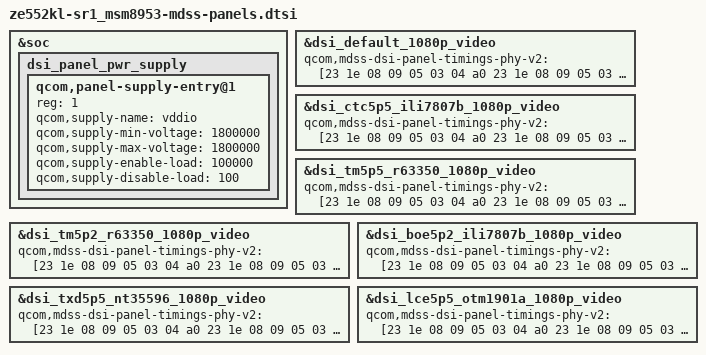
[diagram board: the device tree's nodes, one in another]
/* Copyright (c) 2015-2017, The Linux Foundation. All rights reserved.
 *
 * This program is free software; you can redistribute it and/or modify
 * it under the terms of the GNU General Public License version 2 and
 * only version 2 as published by the Free Software Foundation.
 *
 * This program is distributed in the hope that it will be useful,
 * but WITHOUT ANY WARRANTY; without even the implied warranty of
 * MERCHANTABILITY or FITNESS FOR A PARTICULAR PURPOSE.  See the
 * GNU General Public License for more details.
 */

/*#include "dsi-panel-sim-video.dtsi"
#include "dsi-panel-sim-dualmipi-video.dtsi"
#include "dsi-panel-sim-cmd.dtsi"
#include "dsi-panel-sim-dualmipi-cmd.dtsi"
#include "dsi-panel-truly-1080p-video.dtsi"
#include "dsi-panel-truly-1080p-cmd.dtsi"
#include "dsi-adv7533-1080p.dtsi"
#include "dsi-adv7533-720p.dtsi"
#include "dsi-panel-r69006-1080p-video.dtsi"
#include "dsi-panel-r69006-1080p-cmd.dtsi"
#include "dsi-panel-truly-wuxga-video.dtsi"
#include "dsi-panel-lt8912-480p-video.dtsi"
#include "dsi-panel-lt8912-1080p-video.dtsi"*/
#include "dsi-panel-default-1080p-video.dtsi"
#include "dsi-panel-ctc5p5-ili7807b-1080p-video.dtsi"
#include "dsi-panel-tm5p5-r63350-1080p-video.dtsi"
#include "dsi-panel-tm5p2-r63350-1080p-video.dtsi"
#include "dsi-panel-boe5p2-ili7807b-1080p-video.dtsi"
#include "dsi-panel-txd5p5-nt35596-1080p-video.dtsi"
#include "dsi-panel-lce5p5-otm1901a-1080p-video.dtsi"

&soc {
	dsi_panel_pwr_supply: dsi_panel_pwr_supply {
		#address-cells = <1>;
		#size-cells = <0>;

		/*qcom,panel-supply-entry@0 {
			reg = <0>;
			qcom,supply-name = "vdd";
			qcom,supply-min-voltage = <2850000>;
			qcom,supply-max-voltage = <2850000>;
			qcom,supply-enable-load = <100000>;
			qcom,supply-disable-load = <100>;
		};*/

		qcom,panel-supply-entry@1 {
			reg = <1>;
			qcom,supply-name = "vddio";
			qcom,supply-min-voltage = <1800000>;
			qcom,supply-max-voltage = <1800000>;
			qcom,supply-enable-load = <100000>;
			qcom,supply-disable-load = <100>;
		};
	};
};

&dsi_default_1080p_video {
	qcom,mdss-dsi-panel-timings-phy-v2 = [23 1e 08 09 05 03 04 a0
		23 1e 08 09 05 03 04 a0
		23 1e 08 09 05 03 04 a0
		23 1e 08 09 05 03 04 a0
		23 1a 08 09 05 03 04 a0];
};

&dsi_ctc5p5_ili7807b_1080p_video {
	qcom,mdss-dsi-panel-timings-phy-v2 = [23 1e 08 09 05 03 04 a0
		23 1e 08 09 05 03 04 a0
		23 1e 08 09 05 03 04 a0
		23 1e 08 09 05 03 04 a0
		23 1a 08 09 05 03 04 a0];
};

&dsi_tm5p5_r63350_1080p_video {
	qcom,mdss-dsi-panel-timings-phy-v2 = [23 1e 08 09 05 03 04 a0
		23 1e 08 09 05 03 04 a0
		23 1e 08 09 05 03 04 a0
		23 1e 08 09 05 03 04 a0
		23 1a 08 09 05 03 04 a0];
};

&dsi_tm5p2_r63350_1080p_video {
	qcom,mdss-dsi-panel-timings-phy-v2 = [23 1e 08 09 05 03 04 a0
		23 1e 08 09 05 03 04 a0
		23 1e 08 09 05 03 04 a0
		23 1e 08 09 05 03 04 a0
		23 1a 08 09 05 03 04 a0];
};

&dsi_boe5p2_ili7807b_1080p_video {
	qcom,mdss-dsi-panel-timings-phy-v2 = [23 1e 08 09 05 03 04 a0
		23 1e 08 09 05 03 04 a0
		23 1e 08 09 05 03 04 a0
		23 1e 08 09 05 03 04 a0
		23 1a 08 09 05 03 04 a0];
};

&dsi_txd5p5_nt35596_1080p_video {
	qcom,mdss-dsi-panel-timings-phy-v2 = [23 1e 08 09 05 03 04 a0
		23 1e 08 09 05 03 04 a0
		23 1e 08 09 05 03 04 a0
		23 1e 08 09 05 03 04 a0
		23 1a 08 09 05 03 04 a0];
};

&dsi_lce5p5_otm1901a_1080p_video {
	qcom,mdss-dsi-panel-timings-phy-v2 = [23 1e 08 09 05 03 04 a0
		23 1e 08 09 05 03 04 a0
		23 1e 08 09 05 03 04 a0
		23 1e 08 09 05 03 04 a0
		23 1a 08 09 05 03 04 a0];
};

/*&dsi_truly_1080_vid {
	qcom,mdss-dsi-panel-timings-phy-v2 = [23 1e 08 09 05 03 04 a0
		23 1e 08 09 05 03 04 a0
		23 1e 08 09 05 03 04 a0
		23 1e 08 09 05 03 04 a0
		23 1a 08 09 05 03 04 a0];
};

&dsi_truly_1080_cmd {
	qcom,mdss-dsi-panel-timings-phy-v2 = [23 1e 08 09 05 03 04 a0
		23 1e 08 09 05 03 04 a0
		23 1e 08 09 05 03 04 a0
		23 1e 08 09 05 03 04 a0
		23 1a 08 09 05 03 04 a0];
};

&dsi_r69006_1080p_video {
	qcom,mdss-dsi-panel-timings-phy-v2 = [24 1f 08 09 05 03 04 a0
		24 1f 08 09 05 03 04 a0
		24 1f 08 09 05 03 04 a0
		24 1f 08 09 05 03 04 a0
		24 1b 08 09 05 03 04 a0];
};

&dsi_r69006_1080p_cmd{
	qcom,mdss-dsi-panel-timings-phy-v2 = [24 1f 08 09 05 03 04 a0
		24 1f 08 09 05 03 04 a0
		24 1f 08 09 05 03 04 a0
		24 1f 08 09 05 03 04 a0
		24 1b 08 09 05 03 04 a0];
};

&dsi_adv7533_1080p {
	qcom,mdss-dsi-panel-timings-phy-v2 = [24 1f 08 09 05 03 04 a0
		24 1f 08 09 05 03 04 a0
		24 1f 08 09 05 03 04 a0
		24 1f 08 09 05 03 04 a0
		24 1b 08 09 05 03 04 a0];
};

&dsi_adv7533_720p {
	qcom,mdss-dsi-panel-timings-phy-v2 = [1e 1b 04 06 02 03 04 a0
		1e 1b 04 06 02 03 04 a0
		1e 1b 04 06 02 03 04 a0
		1e 1b 04 06 02 03 04 a0
		1e 0e 04 05 02 03 04 a0];
};

&dsi_truly_wuxga_vid {
	qcom,mdss-dsi-panel-timings-phy-v2 = [24 1f 08 09 05 03 04 a0
		24 1f 08 09 05 03 04 a0
		24 1f 08 09 05 03 04 a0
		24 1f 08 09 05 03 04 a0
		24 1c 08 09 05 03 04 a0];
};*/
